VERSION ""

NS_ :

BS_:

BU_: TMS

BO_ 1160 TMS_PDO_4: 8 TMS

BO_ 904 TMS_PDO_3: 8 TMS

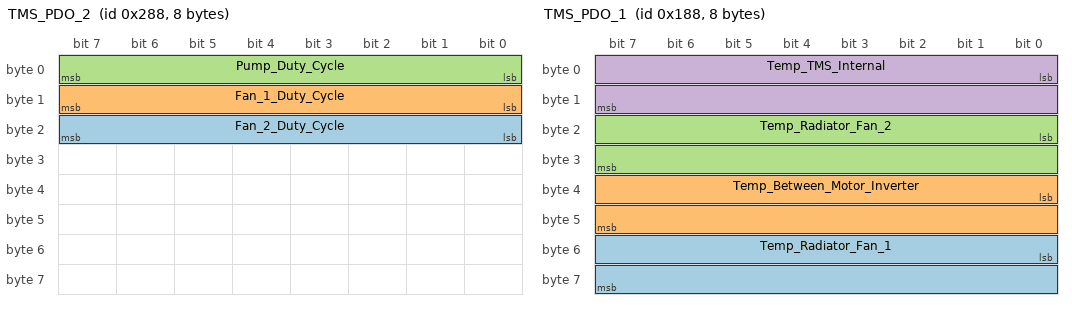
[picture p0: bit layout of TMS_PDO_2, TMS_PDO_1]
BO_ 648 TMS_PDO_2: 8 TMS
 SG_ Fan_2_Duty_Cycle : 16|8@1+ (1,0) [0|255] "" Vector__XXX
 SG_ Fan_1_Duty_Cycle : 8|8@1+ (1,0) [0|255] "" Vector__XXX
 SG_ Pump_Duty_Cycle : 0|8@1+ (1,0) [0|255] "" Vector__XXX

BO_ 392 TMS_PDO_1: 8 TMS
 SG_ Temp_Radiator_Fan_1 : 48|16@1+ (0.001,0) [0|65.535] "" Vector__XXX
 SG_ Temp_Between_Motor_Inverter : 32|16@1+ (0.001,0) [0|65.535] "" Vector__XXX
 SG_ Temp_Radiator_Fan_2 : 16|16@1+ (0.001,0) [0|65.535] "" Vector__XXX
 SG_ Temp_TMS_Internal : 0|16@1+ (0.001,0) [0|65.535] "" Vector__XXX

BA_DEF_  "BusType" STRING ;
BA_DEF_DEF_  "BusType" "CAN";
